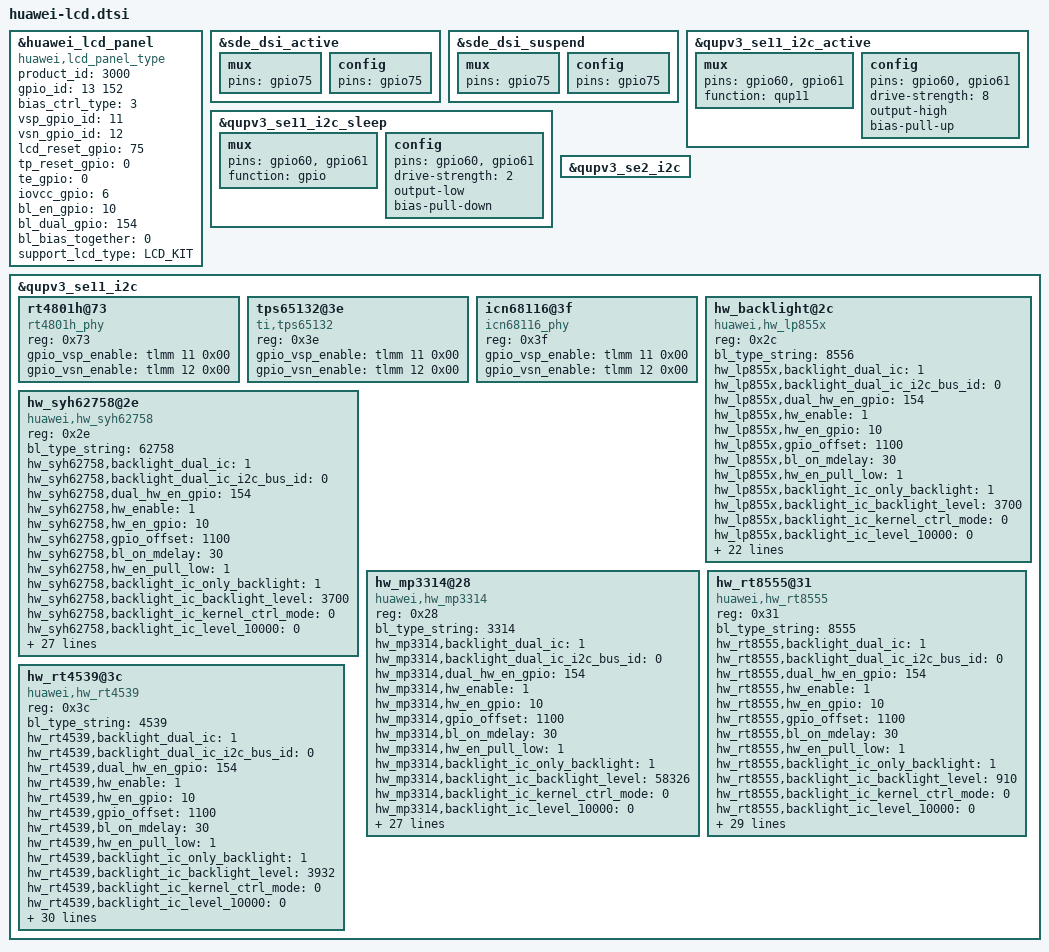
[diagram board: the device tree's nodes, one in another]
#include "../../../lcdkit3.0/marx/devkit_lcd_kit.dtsi"
&huawei_lcd_panel {
	compatible = "huawei,lcd_panel_type";
	/* auto_key_info @ name: product_id type: uint32 default: 0 */
	product_id = <3000>;
	/* auto_key_info @ name: gpio_id[2] type: int default: 0 */
	gpio_id = <13 152>;
	/* auto_key_info @ name: bias_ctrl_type type: uint32 default: 0 */
	bias_ctrl_type = <3>;
	/* auto_key_info @ name: vsp_gpio_id type: uint32 default: 0 */
	vsp_gpio_id = <11>;
	/* auto_key_info @ name: vsn_gpio_id type: uint32 default: 0 */
	vsn_gpio_id = <12>;
	/* auto_key_info @ name: lcd_reset_gpio type: uint32 default: 0 */
	lcd_reset_gpio = <75>;
	/* auto_key_info @ name: tp_reset_gpio type: uint32 default: 0 */
	tp_reset_gpio = <0>;
	/* auto_key_info @ name: te_gpio type: uint32 default: 0 */
	te_gpio = <0>;
	/* auto_key_info @ name: iovcc_gpio type: uint32 default: 0 */
	iovcc_gpio = <6>;
	/* auto_key_info @ name: bl_en_gpio type: uint32 default: 0 */
	bl_en_gpio = <10>;
	/* auto_key_info @ name: bl_dual_gpio type: uint32 default: 0 */
	bl_dual_gpio = <154>;
	/* auto_key_info @ name: bl_bias_together type: uint32 default: 1 */
	bl_bias_together = <0>;
	support_lcd_type = "LCD_KIT";
};

&sde_dsi_active {
		mux {
			pins = "gpio75";
		};
		config {
			pins = "gpio75";
		};
};
&sde_dsi_suspend {
		mux {
			pins = "gpio75";
        };
		config {
			pins = "gpio75";
		};
};

&qupv3_se11_i2c_active {
		mux {
			pins = "gpio60", "gpio61";
			function = "qup11";
		};
		config {
			pins = "gpio60", "gpio61";
			drive-strength = <8>;
			output-high;
			bias-pull-up;
		};
};

&qupv3_se11_i2c_sleep {
		mux {
			pins = "gpio60", "gpio61";
			function = "gpio";
		};
		config {
			pins = "gpio60", "gpio61";
			drive-strength = <2>;
			output-low;
			bias-pull-down;
		};
};

&qupv3_se2_i2c {
        status = "ok";
        #address-cells = <1>;
        #size-cells = <0>;
};

&qupv3_se11_i2c {
	status = "ok";
	#address-cells = <1>;
	#size-cells = <0>;

	rt4801h@73 {
			compatible = "rt4801h_phy";
			reg = <0x73>;
			gpio_vsp_enable = <&tlmm 11 0x00>;
			gpio_vsn_enable = <&tlmm 12 0x00>;
	};
	tps65132@3e {
			compatible = "ti,tps65132";
			reg = <0x3e>;
			gpio_vsp_enable = <&tlmm 11 0x00>;
			gpio_vsn_enable = <&tlmm 12 0x00>;
	};
	icn68116@3f {
		compatible = "icn68116_phy";
		reg = <0x3f>;
		gpio_vsp_enable = <&tlmm 11 0x00>;
		gpio_vsn_enable = <&tlmm 12 0x00>;
	};

	hw_backlight@2c {
		status = "ok";
		compatible = "huawei,hw_lp855x";
		reg = <0x2c>;
		bl_type_string = "8556";

		hw_lp855x,backlight_dual_ic = <1>;
		hw_lp855x,backlight_dual_ic_i2c_bus_id = <0>;
		hw_lp855x,dual_hw_en_gpio = <154>;
		hw_lp855x,hw_enable = <1>;
		hw_lp855x,hw_en_gpio = <10>;
		hw_lp855x,gpio_offset = <1100>;
		hw_lp855x,bl_on_mdelay = <30>;
		hw_lp855x,hw_en_pull_low = <1>;
		hw_lp855x,backlight_ic_only_backlight = <1>;
		hw_lp855x,backlight_ic_backlight_level = <3700>;
		hw_lp855x,backlight_ic_kernel_ctrl_mode = <0>;
		hw_lp855x,backlight_ic_level_10000 = <0>;
		hw_lp855x,backlight_ic_bits_compatible = <1>;
		hw_lp855x,backlight_ic_level_lsb_cmd = <0x08 0x10 0x00 0xff>;
		hw_lp855x,backlight_ic_level_msb_cmd = <0x04 0x11 0x00 0x0f>;
		hw_lp855x,backlight_ic_pull_boost_support = <0>;
		hw_lp855x,backlight_ic_pull_boost_delay = <0>;
		hw_lp855x,backlight_ic_pull_down_vsp_cmd = <0x01 0x0d 0x00 0xff 0x00>;
		hw_lp855x,backlight_ic_pull_down_vsn_cmd = <0x01 0x0e 0x00 0xff 0x00>;
		hw_lp855x,backlight_ic_pull_down_boost_cmd = <0x01 0x0c 0x14 0xff 0x00>;
		hw_lp855x,backlight_ic_fault_check_support = <1>;
		hw_lp855x,backlight_ic_ocp_flag_cmd = <0x00 0x02 0x04 0x04 0x00>;
		hw_lp855x,backlight_ic_kernel_init_cmd = <0x01 0x01 0x85 0xff 0x00
						0x01 0xa0 0xff 0xff 0x00
						0x01 0xa1 0xbf 0xff 0x00
						0x01 0xa2 0x28 0xff 0x00
						0x01 0xa3 0x52 0xff 0x00
						0x01 0xa4 0x12 0xff 0x00
						0x01 0xa5 0x10 0xff 0x00
						0x01 0xa6 0x40 0xff 0x00
						0x01 0xa7 0xf7 0xff 0x00
						0x01 0xa9 0x80 0xff 0x00
						0x01 0xaa 0x0f 0xff 0x00
						0x01 0xae 0x0e 0xff 0x00
						0x01 0x9e 0x22 0xff 0x00
						0x01 0x16 0x1f 0xff 0x00>;
		hw_lp855x,backlight_ic_num_of_kernel_init_cmd = <14>;
		hw_lp855x,backlight_ic_init_vsp_index = <14>;
		hw_lp855x,backlight_ic_init_vsn_index = <15>;
	};

	hw_syh62758@2e {
		status = "ok";
		compatible = "huawei,hw_syh62758";
		reg = <0x2e>;
		bl_type_string = "62758";

		hw_syh62758,backlight_dual_ic = <1>;
		hw_syh62758,backlight_dual_ic_i2c_bus_id = <0>;
		hw_syh62758,dual_hw_en_gpio = <154>;
		hw_syh62758,hw_enable = <1>;
		hw_syh62758,hw_en_gpio = <10>;
		hw_syh62758,gpio_offset = <1100>;
		hw_syh62758,bl_on_mdelay = <30>;
		hw_syh62758,hw_en_pull_low = <1>;
		hw_syh62758,backlight_ic_only_backlight = <1>;
		hw_syh62758,backlight_ic_backlight_level = <3700>;
		hw_syh62758,backlight_ic_kernel_ctrl_mode = <0>;
		hw_syh62758,backlight_ic_level_10000 = <0>;
		hw_syh62758,backlight_ic_bits_compatible = <1>;
		hw_syh62758,backlight_ic_level_lsb_cmd = <0x08 0x10 0x00 0xff>;
		hw_syh62758,backlight_ic_level_msb_cmd = <0x04 0x11 0x00 0x0f>;
		hw_syh62758,backlight_ic_pull_boost_support = <0>;
		hw_syh62758,backlight_ic_pull_boost_delay = <0>;
		hw_syh62758,backlight_ic_pull_down_vsp_cmd = <0x01 0x0d 0x00 0xff 0x00>;
		hw_syh62758,backlight_ic_pull_down_vsn_cmd = <0x01 0x0e 0x00 0xff 0x00>;
		hw_syh62758,backlight_ic_pull_down_boost_cmd = <0x01 0x0c 0x14 0xff 0x00>;
		hw_syh62758,backlight_ic_fault_check_support = <0>;
		hw_syh62758,backlight_ic_ovp_flag_cmd = <0x00 0x0f 0x02 0x02 0x00>;
		hw_syh62758,backlight_ic_ocp_flag_cmd = <0x00 0x0f 0x01 0x01 0x00>;
		hw_syh62758,backlight_ic_tsd_flag_cmd = <0x00 0x0f 0x40 0x40 0x00>;
		hw_syh62758,backlight_ic_kernel_init_cmd = <0x01 0x01 0x85 0xff 0x00
						0x01 0xa2 0x20 0xff 0x00
						0x01 0xa0 0xff 0xff 0x00
						0x01 0xa1 0xbf 0xff 0x00
						0x01 0xa3 0x3e 0xff 0x00
						0x01 0xa4 0x02 0xff 0x00
						0x01 0xa5 0x10 0xff 0x00
						0x01 0xa6 0x40 0xff 0x00
						0x01 0xa7 0xf7 0xff 0x00
						0x01 0xa9 0x80 0xff 0x00
						0x01 0xaa 0x0f 0xff 0x00
						0x01 0xae 0x0e 0xff 0x00
						0x01 0x9e 0x22 0xff 0x00
						0x01 0x16 0x1f 0xff 0x00
						0x01 0x00 0x00 0xff 0x00
						0x01 0x01 0x84 0xff 0x02
						0x01 0x9e 0x02 0xff 0x01
						0x01 0x9e 0x22 0xff 0x00>;
		hw_syh62758,backlight_ic_num_of_kernel_init_cmd = <18>;
		hw_syh62758,backlight_ic_init_vsp_index = <14>;
		hw_syh62758,backlight_ic_init_vsn_index = <15>;
	};

	hw_mp3314@28 {
		status = "ok";
		compatible = "huawei,hw_mp3314";
		reg = <0x28>;
		bl_type_string = "3314";

		hw_mp3314,backlight_dual_ic = <1>;
		hw_mp3314,backlight_dual_ic_i2c_bus_id = <0>;
		hw_mp3314,dual_hw_en_gpio = <154>;
		hw_mp3314,hw_enable = <1>;
		hw_mp3314,hw_en_gpio = <10>;
		hw_mp3314,gpio_offset = <1100>;
		hw_mp3314,bl_on_mdelay = <30>;
		hw_mp3314,hw_en_pull_low = <1>;
		hw_mp3314,backlight_ic_only_backlight = <1>;
		hw_mp3314,backlight_ic_backlight_level = <58326>;
		hw_mp3314,backlight_ic_kernel_ctrl_mode = <0>;
		hw_mp3314,backlight_ic_level_10000 = <0>;
		hw_mp3314,backlight_ic_bits_compatible = <1>;
		hw_mp3314,backlight_ic_set_msb_before_lsb = <1>;
		hw_mp3314,backlight_ic_level_lsb_cmd = <0x08 0x01 0x00 0xff>;
		hw_mp3314,backlight_ic_level_msb_cmd = <0x08 0x00 0x00 0xff>;
		hw_mp3314,backlight_ic_pull_boost_support = <0>;
		hw_mp3314,backlight_ic_pull_boost_delay = <0>;
		hw_mp3314,backlight_ic_pull_down_vsp_cmd = <0x01 0x0d 0x00 0xff 0x00>;
		hw_mp3314,backlight_ic_pull_down_vsn_cmd = <0x01 0x0e 0x00 0xff 0x00>;
		hw_mp3314,backlight_ic_pull_down_boost_cmd = <0x01 0x0c 0x14 0xff 0x00>;
		hw_mp3314,backlight_ic_fault_check_support = <0>;
		hw_mp3314,backlight_ic_ovp_flag_cmd = <0x00 0x0f 0x02 0x02 0x00>;
		hw_mp3314,backlight_ic_ocp_flag_cmd = <0x00 0x0f 0x01 0x01 0x00>;
		hw_mp3314,backlight_ic_tsd_flag_cmd = <0x00 0x0f 0x40 0x40 0x00>;
		hw_mp3314,backlight_ic_kernel_init_cmd = <0x01 0x02 0x9a 0xff 0x00
						0x01 0x00 0x00 0xff 0x00
						0x01 0x01 0x00 0xff 0x00
						0x01 0x03 0x5f 0xff 0x00
						0x01 0x04 0xa0 0xff 0x00
						0x01 0x05 0x08 0xff 0x00
						0x01 0x06 0xff 0xff 0x00
						0x01 0x07 0x3f 0xff 0x00
						0x01 0x08 0xa0 0xff 0x00
						0x01 0x09 0xA2 0xff 0x00
						0x01 0x0a 0x90 0xff 0x00
						0x01 0x0b 0x67 0xff 0x00
						0x01 0x0c 0x00 0xff 0x00
						0x01 0x0d 0x00 0xff 0x00
						0x01 0x0e 0x00 0xff 0x00
						0x01 0x0f 0x2f 0xff 0x00
						0x01 0x10 0xc0 0xff 0x00
						0x01 0x11 0x00 0xff 0x00
						0x01 0x1d 0x11 0xff 0x00
						0x01 0x02 0x9B 0xff 0x00>;
		hw_mp3314,backlight_ic_num_of_kernel_init_cmd = <20>;
		hw_mp3314,backlight_ic_init_vsp_index = <14>;
		hw_mp3314,backlight_ic_init_vsn_index = <15>;
	};

	hw_rt8555@31 {
		status = "ok";
		compatible = "huawei,hw_rt8555";
		reg = <0x31>;
		bl_type_string = "8555";

		hw_rt8555,backlight_dual_ic = <1>;
		hw_rt8555,backlight_dual_ic_i2c_bus_id = <0>;
		hw_rt8555,dual_hw_en_gpio = <154>;
		hw_rt8555,hw_enable = <1>;
		hw_rt8555,hw_en_gpio = <10>;
		hw_rt8555,gpio_offset = <1100>;
		hw_rt8555,bl_on_mdelay = <30>;
		hw_rt8555,hw_en_pull_low = <1>;
		hw_rt8555,backlight_ic_only_backlight = <1>;
		hw_rt8555,backlight_ic_backlight_level = <910>;
		hw_rt8555,backlight_ic_kernel_ctrl_mode = <0>;
		hw_rt8555,backlight_ic_level_10000 = <0>;
		hw_rt8555,backlight_ic_bits_compatible = <1>;
		hw_rt8555,backlight_ic_level_lsb_cmd = <0x08 0x04 0x00 0xff>;
		hw_rt8555,backlight_ic_level_msb_cmd = <0x02 0x05 0x00 0x03>;
		hw_rt8555,dimming_support = <1>;
		hw_rt8555,dimming_config_reg = <0x08>;
		hw_rt8555,dimming_config = <0x70>;
		hw_rt8555,backlight_ic_pull_boost_support = <0>;
		hw_rt8555,backlight_ic_pull_boost_delay = <0>;
		hw_rt8555,backlight_ic_pull_down_vsp_cmd = <0x01 0x0d 0x00 0xff 0x00>;
		hw_rt8555,backlight_ic_pull_down_vsn_cmd = <0x01 0x0e 0x00 0xff 0x00>;
		hw_rt8555,backlight_ic_pull_down_boost_cmd = <0x01 0x0c 0x14 0xff 0x00>;
		hw_rt8555,backlight_ic_fault_check_support = <0>;
		hw_rt8555,backlight_ic_ovp_flag_cmd = <0x00 0x0f 0x02 0x02 0x00>;
		hw_rt8555,backlight_ic_ocp_flag_cmd = <0x00 0x0f 0x01 0x01 0x00>;
		hw_rt8555,backlight_ic_tsd_flag_cmd = <0x00 0x0f 0x40 0x40 0x00>;
		hw_rt8555,backlight_ic_kernel_init_cmd = <0x01 0x00 0xc3 0xff 0x00
						0x01 0x01 0xc7 0xff 0x00
						0x01 0x02 0x92 0xff 0x00
						0x01 0x03 0x00 0xff 0x00
						0x01 0x08 0x10 0xff 0x00
						0x01 0x09 0x7f 0xff 0x00
						0x01 0x0a 0x04 0xff 0x00
						0x01 0x0b 0x00 0xff 0x00
						0x01 0x0d 0x00 0xff 0x00
						0x01 0x0e 0x00 0xff 0x00
						0x01 0x50 0x01 0xff 0x00>;
		hw_rt8555,backlight_ic_num_of_kernel_init_cmd = <11>;
		hw_rt8555,backlight_ic_init_vsp_index = <14>;
		hw_rt8555,backlight_ic_init_vsn_index = <15>;
	};

	hw_rt4539@3c {
		status = "ok";
		compatible = "huawei,hw_rt4539";
		reg = <0x3c>;
		bl_type_string = "4539";

		hw_rt4539,backlight_dual_ic = <1>;
		hw_rt4539,backlight_dual_ic_i2c_bus_id = <0>;
		hw_rt4539,dual_hw_en_gpio = <154>;
		hw_rt4539,hw_enable = <1>;
		hw_rt4539,hw_en_gpio = <10>;
		hw_rt4539,gpio_offset = <1100>;
		hw_rt4539,bl_on_mdelay = <30>;
		hw_rt4539,hw_en_pull_low = <1>;
		hw_rt4539,backlight_ic_only_backlight = <1>;
		hw_rt4539,backlight_ic_backlight_level = <3932>;
		hw_rt4539,backlight_ic_kernel_ctrl_mode = <0>;
		hw_rt4539,backlight_ic_level_10000 = <0>;
		hw_rt4539,backlight_ic_bits_compatible = <1>;
		hw_rt4539,backlight_ic_level_lsb_cmd = <0x08 0x05 0x00 0xff>;
		hw_rt4539,backlight_ic_level_msb_cmd = <0x04 0x04 0x00 0x0f>;
		hw_rt4539,backlight_ic_set_msb_before_lsb = <1>;
		hw_rt4539,dimming_support = <0>;
		hw_rt4539,dimming_config_reg = <0x08>;
		hw_rt4539,dimming_config = <0x70>;
		hw_rt4539,backlight_ic_pull_boost_support = <0>;
		hw_rt4539,backlight_ic_pull_boost_delay = <0>;
		hw_rt4539,backlight_ic_pull_down_vsp_cmd = <0x01 0x0d 0x00 0xff 0x00>;
		hw_rt4539,backlight_ic_pull_down_vsn_cmd = <0x01 0x0e 0x00 0xff 0x00>;
		hw_rt4539,backlight_ic_pull_down_boost_cmd = <0x01 0x0c 0x14 0xff 0x00>;
		hw_rt4539,backlight_ic_fault_check_support = <0>;
		hw_rt4539,backlight_ic_ovp_flag_cmd = <0x00 0x0f 0x02 0x02 0x00>;
		hw_rt4539,backlight_ic_ocp_flag_cmd = <0x00 0x0f 0x01 0x01 0x00>;
		hw_rt4539,backlight_ic_tsd_flag_cmd = <0x00 0x0f 0x40 0x40 0x00>;
		hw_rt4539,backlight_ic_kernel_init_cmd = <0x01 0x00 0x24 0xff 0x00
						0x01 0x01 0x18 0xff 0x00
						0x01 0x02 0x82 0xff 0x00
						0x01 0x03 0x24 0xff 0x00
						0x01 0x06 0x90 0xff 0x00
						0x01 0x07 0x01 0xff 0x00
						0x01 0x08 0x02 0xff 0x00
						0x01 0x09 0x78 0xff 0x00
						0x01 0x0a 0x14 0xff 0x00
						0x01 0x0b 0xbe 0xff 0x00
						0x01 0xff 0x00 0xff 0x00>;
		hw_rt4539,backlight_ic_num_of_kernel_init_cmd = <11>;
		hw_rt4539,backlight_ic_init_vsp_index = <14>;
		hw_rt4539,backlight_ic_init_vsn_index = <15>;
	};
};
